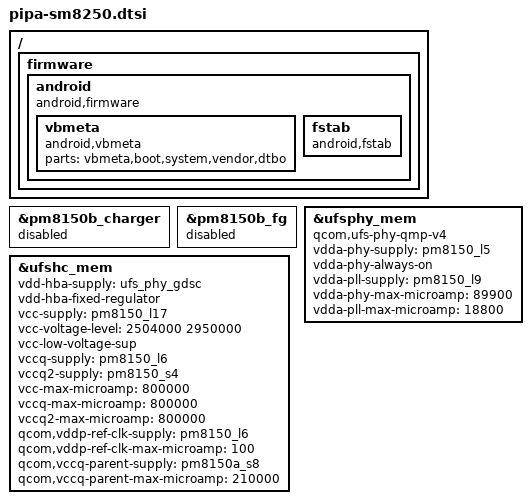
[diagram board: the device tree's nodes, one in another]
#include "pipa-pmic-base.dtsi"
#include "pipa-usb.dtsi"

&pm8150b_charger {
	status = "disabled";
};

&pm8150b_fg {
	status = "disabled";
};

&ufsphy_mem {
	compatible = "qcom,ufs-phy-qmp-v4";
	vdda-phy-supply = <&pm8150_l5>;
	vdda-phy-always-on;
	vdda-pll-supply = <&pm8150_l9>;
	vdda-phy-max-microamp = <89900>;
	vdda-pll-max-microamp = <18800>;
	status = "ok";
};

&ufshc_mem {
	vdd-hba-supply = <&ufs_phy_gdsc>;
	vdd-hba-fixed-regulator;
	vcc-supply = <&pm8150_l17>;
	vcc-voltage-level = <2504000 2950000>;
	vcc-low-voltage-sup;
	vccq-supply = <&pm8150_l6>;
	vccq2-supply = <&pm8150_s4>;
	vcc-max-microamp = <800000>;
	vccq-max-microamp = <800000>;
	vccq2-max-microamp = <800000>;
	qcom,vddp-ref-clk-supply = <&pm8150_l6>;
	qcom,vddp-ref-clk-max-microamp = <100>;
	qcom,vccq-parent-supply = <&pm8150a_s8>;
	qcom,vccq-parent-max-microamp = <210000>;
	status = "ok";
};

/ {
	firmware {
		android {
			compatible = "android,firmware";
			vbmeta {
				compatible = "android,vbmeta";
				parts = "vbmeta,boot,system,vendor,dtbo";
			};

			fstab {
				compatible = "android,fstab";
			};
		};
	};
};
